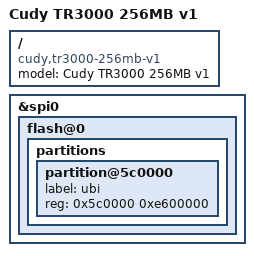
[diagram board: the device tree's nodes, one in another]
// SPDX-License-Identifier: (GPL-2.0 OR MIT)

#include "mt7981b-cudy-tr3000-v1.dts"

/ {
	model = "Cudy TR3000 256MB v1";
	compatible = "cudy,tr3000-256mb-v1", "mediatek,mt7981";
};

&spi0 {
	flash@0 {
		partitions {
			partition@5c0000 {
				label = "ubi";
				reg = <0x5c0000 0xe600000>;
			};
		};
	};
};
